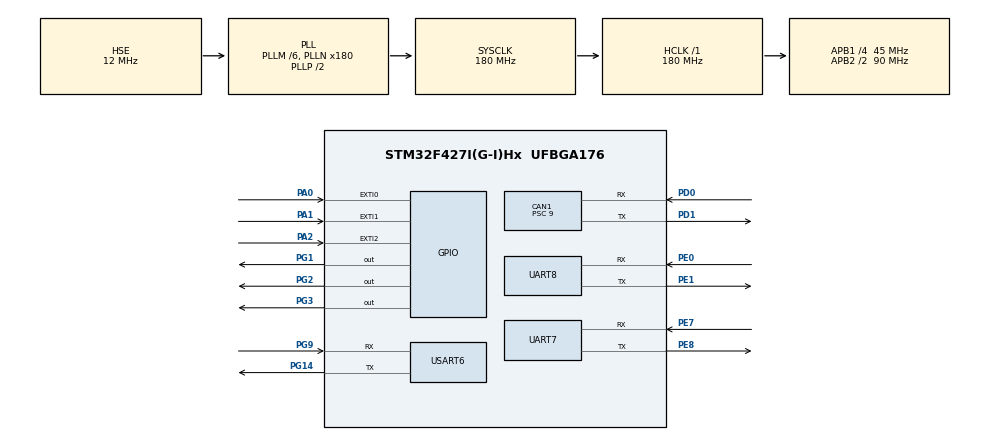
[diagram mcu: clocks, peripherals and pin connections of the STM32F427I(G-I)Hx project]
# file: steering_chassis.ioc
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CAN1.ABOM=DISABLE
CAN1.BS1=CAN_BS1_3TQ
CAN1.BS2=CAN_BS2_1TQ
CAN1.CalculateBaudRate=1000000
CAN1.CalculateTimeBit=1000
CAN1.CalculateTimeQuantum=200.0
CAN1.Prescaler=9
FREERTOS.Tasks01=defaultTask,8,128,StartDefaultTask,Default,NULL,Dynamic,NULL,NULL
Mcu.Family=STM32F4
Mcu.Name=STM32F427I(G-I)Hx
Mcu.Package=UFBGA176
NVIC.CAN1_RX0_IRQn=true\:5\:0\:false\:false\:true\:true\:true\:true\:true
NVIC.EXTI0_IRQn=true\:5\:0\:false\:false\:true\:true\:true\:true\:true
NVIC.EXTI1_IRQn=true\:5\:0\:false\:false\:true\:true\:true\:true\:true
NVIC.EXTI2_IRQn=true\:5\:0\:false\:false\:true\:true\:true\:true\:true
NVIC.PriorityGroup=NVIC_PRIORITYGROUP_4
NVIC.TIM1_UP_TIM10_IRQn=true\:15\:0\:false\:false\:true\:false\:false\:true\:true
NVIC.TimeBase=TIM1_UP_TIM10_IRQn
NVIC.TimeBaseIP=TIM1
NVIC.UART7_IRQn=true\:5\:0\:false\:false\:true\:true\:true\:true\:true
NVIC.UART8_IRQn=true\:5\:0\:false\:false\:true\:true\:true\:true\:true
NVIC.USART6_IRQn=true\:5\:0\:false\:false\:true\:true\:true\:true\:true
PA0/WKUP.GPIO_PuPd=GPIO_PULLDOWN
PA0/WKUP.Signal=GPXTI0
PA1.GPIO_PuPd=GPIO_PULLDOWN
PA1.Signal=GPXTI1
PA13.Mode=Serial_Wire
PA13.Signal=SYS_JTMS-SWDIO
PA14.Mode=Serial_Wire
PA14.Signal=SYS_JTCK-SWCLK
PA2.GPIO_PuPd=GPIO_PULLDOWN
PA2.Signal=GPXTI2
PB12.Signal=CAN2_RX
PB13.Signal=CAN2_TX
PC14/OSC32_IN.Mode=LSE-External-Clock-Source
PC14/OSC32_IN.Signal=RCC_OSC32_IN
PC15/OSC32_OUT.Mode=LSE-External-Clock-Source
PC15/OSC32_OUT.Signal=RCC_OSC32_OUT
PD0.Mode=CAN_Activate
PD0.Signal=CAN1_RX
PD1.Mode=CAN_Activate
PD1.Signal=CAN1_TX
PE0.Mode=Asynchronous
PE0.Signal=UART8_RX
PE1.Mode=Asynchronous
PE1.Signal=UART8_TX
PE7.Mode=Asynchronous
PE7.Signal=UART7_RX
PE8.Mode=Asynchronous
PE8.Signal=UART7_TX
PG1.GPIO_ModeDefaultOutputPP=GPIO_MODE_OUTPUT_PP
PG1.GPIO_PuPd=GPIO_PULLUP
PG1.Signal=GPIO_Output
PG14.Mode=Asynchronous
PG14.Signal=USART6_TX
PG2.GPIO_PuPd=GPIO_PULLUP
PG2.Signal=GPIO_Output
PG3.GPIO_PuPd=GPIO_PULLUP
PG3.Signal=GPIO_Output
PG9.Mode=Asynchronous
PG9.Signal=USART6_RX
PH0/OSC_IN.Mode=HSE-External-Oscillator
PH0/OSC_IN.Signal=RCC_OSC_IN
PH1/OSC_OUT.Mode=HSE-External-Oscillator
PH1/OSC_OUT.Signal=RCC_OSC_OUT
ProjectManager.HeapSize=0x200
ProjectManager.StackSize=0x400
ProjectManager.TargetToolchain=Makefile
RCC.48MHZClocksFreq_Value=90000000
RCC.AHBFreq_Value=180000000
RCC.APB1CLKDivider=RCC_HCLK_DIV4
RCC.APB1Freq_Value=45000000
RCC.APB1TimFreq_Value=90000000
RCC.APB2CLKDivider=RCC_HCLK_DIV2
RCC.APB2Freq_Value=90000000
RCC.APB2TimFreq_Value=180000000
RCC.CortexFreq_Value=180000000
RCC.HCLKFreq_Value=180000000
RCC.HSE_VALUE=12000000
RCC.HSI_VALUE=16000000
RCC.LSE_VALUE=32768
RCC.PLLM=6
RCC.PLLN=180
RCC.PLLSourceVirtual=RCC_PLLSOURCE_HSE
RCC.SYSCLKFreq_VALUE=180000000
RCC.SYSCLKSource=RCC_SYSCLKSOURCE_PLLCLK
RCC.VCOOutputFreq_Value=360000000
UART7.VirtualMode=Asynchronous
UART8.VirtualMode=Asynchronous
USART6.VirtualMode=VM_ASYNC
VP_FREERTOS_VS_CMSIS_V2.Mode=CMSIS_V2
VP_SYS_VS_tim1.Mode=TIM1
VP_TIM6_VS_ClockSourceINT.Mode=Enable_Timer
board=custom

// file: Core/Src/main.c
/* USER CODE BEGIN Header */
/**
  ******************************************************************************
  * @file           : main.c
  * @brief          : Main program body
  ******************************************************************************
  * @attention
  *
  * Copyright (c) 2024 STMicroelectronics.
  * All rights reserved.
  *
  * This software is licensed under terms that can be found in the LICENSE file
  * in the root directory of this software component.
  * If no LICENSE file comes with this software, it is provided AS-IS.
  *
  ******************************************************************************
  */
/* USER CODE END Header */
#include "main.h"
#include "cmsis_os.h"
#include "can.h"
#include "tim.h"
#include "usart.h"
#include "gpio.h"

void SystemClock_Config(void);
void MX_FREERTOS_Init(void);

int main(void)
{

  /* MCU Configuration--------------------------------------------------------*/

  /* Reset of all peripherals, Initializes the Flash interface and the Systick. */
  HAL_Init();

  /* Configure the system clock */
  SystemClock_Config();

  /* Initialize all configured peripherals */
  MX_GPIO_Init();
  MX_CAN1_Init();
  MX_USART6_UART_Init();
  MX_UART7_Init();
  MX_UART8_Init();
  MX_TIM6_Init();

  /* Init scheduler */
  osKernelInitialize();

  /* Call init function for freertos objects (in cmsis_os2.c) */
  MX_FREERTOS_Init();

  /* Start scheduler */
  osKernelStart();

  /* We should never get here as control is now taken by the scheduler */

  /* Infinite loop */
  while (1)
  {

  }
}

void SystemClock_Config(void)
{
  RCC_OscInitTypeDef RCC_OscInitStruct = {0};
  RCC_ClkInitTypeDef RCC_ClkInitStruct = {0};

  /** Configure the main internal regulator output voltage
  */
  __HAL_RCC_PWR_CLK_ENABLE();
  __HAL_PWR_VOLTAGESCALING_CONFIG(PWR_REGULATOR_VOLTAGE_SCALE1);

  /** Initializes the RCC Oscillators according to the specified parameters
  * in the RCC_OscInitTypeDef structure.
  */
  RCC_OscInitStruct.OscillatorType = RCC_OSCILLATORTYPE_HSE;
  RCC_OscInitStruct.HSEState = RCC_HSE_ON;
  RCC_OscInitStruct.PLL.PLLState = RCC_PLL_ON;
  RCC_OscInitStruct.PLL.PLLSource = RCC_PLLSOURCE_HSE;
  RCC_OscInitStruct.PLL.PLLM = 6;
  RCC_OscInitStruct.PLL.PLLN = 180;
  RCC_OscInitStruct.PLL.PLLP = RCC_PLLP_DIV2;
  RCC_OscInitStruct.PLL.PLLQ = 4;
  if (HAL_RCC_OscConfig(&RCC_OscInitStruct) != HAL_OK)
  {
    Error_Handler();
  }

  /** Activate the Over-Drive mode
  */
  if (HAL_PWREx_EnableOverDrive() != HAL_OK)
  {
    Error_Handler();
  }

  /** Initializes the CPU, AHB and APB buses clocks
  */
  RCC_ClkInitStruct.ClockType = RCC_CLOCKTYPE_HCLK|RCC_CLOCKTYPE_SYSCLK
                              |RCC_CLOCKTYPE_PCLK1|RCC_CLOCKTYPE_PCLK2;
  RCC_ClkInitStruct.SYSCLKSource = RCC_SYSCLKSOURCE_PLLCLK;
  RCC_ClkInitStruct.AHBCLKDivider = RCC_SYSCLK_DIV1;
  RCC_ClkInitStruct.APB1CLKDivider = RCC_HCLK_DIV4;
  RCC_ClkInitStruct.APB2CLKDivider = RCC_HCLK_DIV2;

  if (HAL_RCC_ClockConfig(&RCC_ClkInitStruct, FLASH_LATENCY_5) != HAL_OK)
  {
    Error_Handler();
  }
}

void HAL_TIM_PeriodElapsedCallback(TIM_HandleTypeDef *htim)
{
  if (htim->Instance == TIM1) {
    HAL_IncTick();
  }
}

void Error_Handler(void)
{
  __disable_irq();
  while (1)
  {
  }
}

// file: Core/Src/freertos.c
/* USER CODE BEGIN Header */
/**
 ******************************************************************************
 * File Name          : freertos.c
 * Description        : Code for freertos applications
 ******************************************************************************
 * @attention
 *
 * Copyright (c) 2024 STMicroelectronics.
 * All rights reserved.
 *
 * This software is licensed under terms that can be found in the LICENSE file
 * in the root directory of this software component.
 * If no LICENSE file comes with this software, it is provided AS-IS.
 *
 ******************************************************************************
 */
/* USER CODE END Header */

#include "FreeRTOS.h"
#include "task.h"
#include "main.h"
#include "cmsis_os.h"

/* USER CODE BEGIN Includes */
#include "allusertask.h"
/* USER CODE END Includes */

/* Definitions for defaultTask */
osThreadId_t defaultTaskHandle;
const osThreadAttr_t defaultTask_attributes = {
  .name = "defaultTask",
  .stack_size = 128 * 4,
  .priority = (osPriority_t) osPriorityLow,
};

void StartDefaultTask(void *argument);

void MX_FREERTOS_Init(void); /* (MISRA C 2004 rule 8.1) */

void MX_FREERTOS_Init(void) {

  /* Create the thread(s) */
  /* creation of defaultTask */
  defaultTaskHandle = osThreadNew(StartDefaultTask, NULL, &defaultTask_attributes);

}

void StartDefaultTask(void *argument)
{
  /* USER CODE BEGIN StartDefaultTask */
    /* Infinite loop */
    User_FREERTOS_Init();
    for (;;) {
        osDelay(5);
    }
  /* USER CODE END StartDefaultTask */
}
